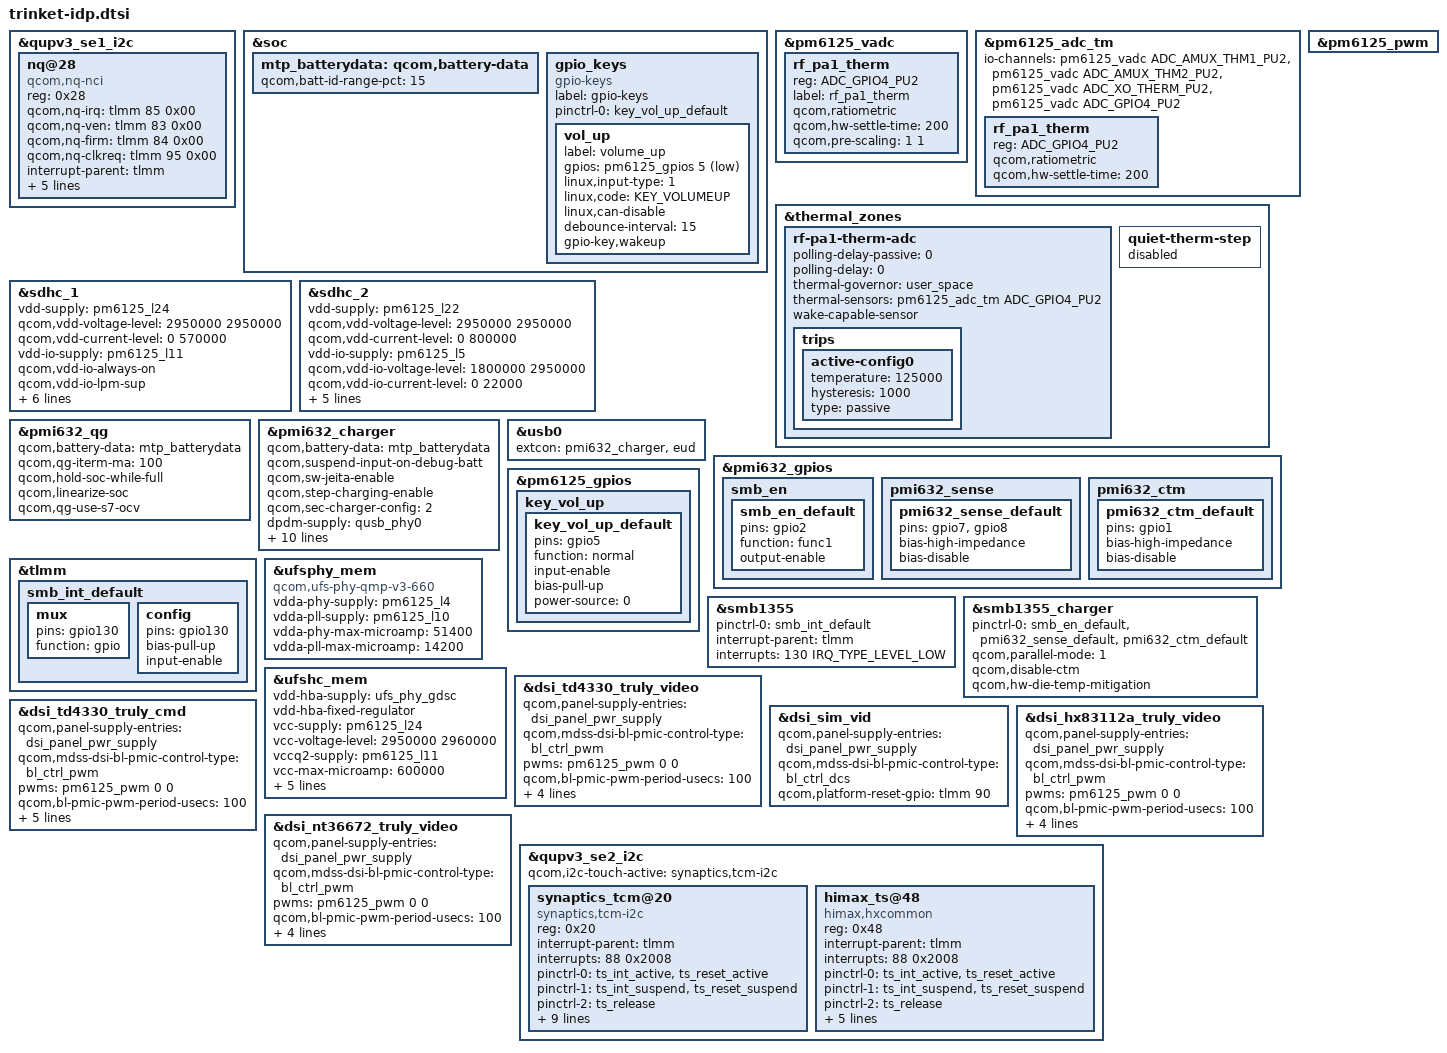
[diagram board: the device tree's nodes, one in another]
/*
 * Copyright (c) 2018-2019, The Linux Foundation. All rights reserved.
 *
 * This program is free software; you can redistribute it and/or modify
 * it under the terms of the GNU General Public License version 2 and
 * only version 2 as published by the Free Software Foundation.
 *
 * This program is distributed in the hope that it will be useful,
 * but WITHOUT ANY WARRANTY; without even the implied warranty of
 * MERCHANTABILITY or FITNESS FOR A PARTICULAR PURPOSE.  See the
 * GNU General Public License for more details.
 */
#include <dt-bindings/gpio/gpio.h>
#include <dt-bindings/input/input.h>
#include <dt-bindings/iio/qcom,spmi-vadc.h>
#include "trinket-thermal-overlay.dtsi"
#include "trinket-sde-display.dtsi"
#include <dt-bindings/clock/qcom,gcc-trinket.h>
#include "trinket-camera-sensor-idp.dtsi"

&qupv3_se1_i2c {
	status = "ok";
	#include "smb1355.dtsi"
};

&soc {
	mtp_batterydata: qcom,battery-data {
		qcom,batt-id-range-pct = <15>;
		#include "qg-batterydata-ascent-3450mah.dtsi"
		#include "qg-batterydata-mlp356477-2800mah.dtsi"
	};
};

&pm6125_vadc {
	rf_pa1_therm {
		reg = <ADC_GPIO4_PU2>;
		label = "rf_pa1_therm";
		qcom,ratiometric;
		qcom,hw-settle-time = <200>;
		qcom,pre-scaling = <1 1>;
	};
};

&pm6125_adc_tm {
	io-channels = <&pm6125_vadc ADC_AMUX_THM1_PU2>,
			<&pm6125_vadc ADC_AMUX_THM2_PU2>,
			<&pm6125_vadc ADC_XO_THERM_PU2>,
			<&pm6125_vadc ADC_GPIO4_PU2>;

	rf_pa1_therm {
		reg = <ADC_GPIO4_PU2>;
		qcom,ratiometric;
		qcom,hw-settle-time = <200>;
	};
};

&thermal_zones {
	rf-pa1-therm-adc {
		polling-delay-passive = <0>;
		polling-delay = <0>;
		thermal-governor = "user_space";
		thermal-sensors = <&pm6125_adc_tm ADC_GPIO4_PU2>;
		wake-capable-sensor;
		trips {
			active-config0 {
				temperature = <125000>;
				hysteresis = <1000>;
				type = "passive";
			};
		};
	};

	quiet-therm-step {
		status = "disabled";
	};
};

&qupv3_se1_i2c {
	status = "ok";
	nq@28 {
		compatible = "qcom,nq-nci";
		reg = <0x28>;
		qcom,nq-irq = <&tlmm 85 0x00>;
		qcom,nq-ven = <&tlmm 83 0x00>;
		qcom,nq-firm = <&tlmm 84 0x00>;
		qcom,nq-clkreq = <&tlmm 95 0x00>;
		interrupt-parent = <&tlmm>;
		interrupts = <85 0>;
		interrupt-names = "nfc_irq";
		pinctrl-names = "nfc_active", "nfc_suspend";
		pinctrl-0 = <&nfc_int_active &nfc_enable_active
				&nfc_clk_req_active>;
		pinctrl-1 = <&nfc_int_suspend &nfc_enable_suspend
				&nfc_clk_req_suspend>;
	};
};

&sdhc_1 {
	vdd-supply = <&pm6125_l24>;
	qcom,vdd-voltage-level = <2950000 2950000>;
	qcom,vdd-current-level = <0 570000>;

	vdd-io-supply = <&pm6125_l11>;
	qcom,vdd-io-always-on;
	qcom,vdd-io-lpm-sup;
	qcom,vdd-io-voltage-level = <1800000 1800000>;
	qcom,vdd-io-current-level = <0 325000>;

	pinctrl-names = "active", "sleep";
	pinctrl-0 = <&sdc1_clk_on &sdc1_cmd_on &sdc1_data_on
					&sdc1_rclk_on>;
	pinctrl-1 = <&sdc1_clk_off &sdc1_cmd_off &sdc1_data_off
					&sdc1_rclk_off>;

	status = "ok";
};

&sdhc_2 {
	vdd-supply = <&pm6125_l22>;
	qcom,vdd-voltage-level = <2950000 2950000>;
	qcom,vdd-current-level = <0 800000>;

	vdd-io-supply = <&pm6125_l5>;
	qcom,vdd-io-voltage-level = <1800000 2950000>;
	qcom,vdd-io-current-level = <0 22000>;

	pinctrl-names = "active", "sleep";
	pinctrl-0 = <&sdc2_clk_on  &sdc2_cmd_on &sdc2_data_on &sdc2_cd_on>;
	pinctrl-1 = <&sdc2_clk_off &sdc2_cmd_off &sdc2_data_off &sdc2_cd_off>;

	cd-gpios = <&tlmm 98 GPIO_ACTIVE_LOW>;

	status = "ok";
};

&pmi632_qg {
	qcom,battery-data = <&mtp_batterydata>;
	qcom,qg-iterm-ma = <100>;
	qcom,hold-soc-while-full;
	qcom,linearize-soc;
	qcom,qg-use-s7-ocv;
};

&pmi632_charger {
	qcom,battery-data = <&mtp_batterydata>;
	qcom,suspend-input-on-debug-batt;
	qcom,sw-jeita-enable;
	qcom,step-charging-enable;
	/* SMB1355 only */
	qcom,sec-charger-config = <2>;
	dpdm-supply = <&qusb_phy0>;
	qcom,charger-temp-max = <800>;
	qcom,smb-temp-max = <800>;
	qcom,auto-recharge-soc = <98>;
	qcom,flash-disable-soc = <10>;
	qcom,hw-die-temp-mitigation;
	qcom,hw-connector-mitigation;
	qcom,connector-internal-pull-kohm = <100>;
	qcom,float-option = <1>;
	qcom,thermal-mitigation = <3000000 2500000
			2000000 1500000 1000000 500000>;
};

&usb0 {
	extcon = <&pmi632_charger>, <&eud>;
};

&pmi632_gpios {
	smb_en {
		smb_en_default: smb_en_default {
			pins = "gpio2";
			function = "func1";
			output-enable;
		};
	};

	pmi632_sense {
		/* GPIO 7 and 8 are external-sense pins for PMI632 */
		pmi632_sense_default: pmi632_sense_default {
			pins = "gpio7", "gpio8";
			bias-high-impedance;	/* disable the GPIO */
			bias-disable;		/* no-pull */
		};
	};

	pmi632_ctm {
		/* Disable GPIO1 for h/w base mitigation */
		pmi632_ctm_default: pmi632_ctm_default {
			pins = "gpio1";
			bias-high-impedance;	/* disable the GPIO */
			bias-disable;		/* no-pull */
		};
	};
};

&pm6125_gpios {
	key_vol_up {
		key_vol_up_default: key_vol_up_default {
			pins = "gpio5";
			function = "normal";
			input-enable;
			bias-pull-up;
			power-source = <0>;
		};
	};
};

&soc {
	gpio_keys {
		compatible = "gpio-keys";
		label = "gpio-keys";

		pinctrl-names = "default";
		pinctrl-0 = <&key_vol_up_default>;

		vol_up {
			label = "volume_up";
			gpios = <&pm6125_gpios 5 GPIO_ACTIVE_LOW>;
			linux,input-type = <1>;
			linux,code = <KEY_VOLUMEUP>;
			linux,can-disable;
			debounce-interval = <15>;
			gpio-key,wakeup;
		};
	};
};

&tlmm {
	smb_int_default: smb_int_default {
		mux {
			pins = "gpio130";
			function = "gpio";
		};
		config {
			pins = "gpio130";
			bias-pull-up;
			input-enable;
		};
	};
};

&smb1355 {
	pinctrl-names = "default";
	pinctrl-0 = <&smb_int_default>;
	interrupt-parent = <&tlmm>;
	interrupts = <130 IRQ_TYPE_LEVEL_LOW>;
	status = "ok";
};

&smb1355_charger {
	pinctrl-names = "default";
	pinctrl-0 = <&smb_en_default &pmi632_sense_default &pmi632_ctm_default>;
	qcom,parallel-mode = <1>;
	qcom,disable-ctm;
	qcom,hw-die-temp-mitigation;
	status = "ok";
};

&ufsphy_mem {
	compatible = "qcom,ufs-phy-qmp-v3-660";

	vdda-phy-supply = <&pm6125_l4>; /* 0.9v */
	vdda-pll-supply = <&pm6125_l10>; /* 1.8v */
	vdda-phy-max-microamp = <51400>;
	vdda-pll-max-microamp = <14200>;

	status = "ok";
};

&ufshc_mem {
	vdd-hba-supply = <&ufs_phy_gdsc>;
	vdd-hba-fixed-regulator;
	vcc-supply = <&pm6125_l24>;
	vcc-voltage-level = <2950000 2960000>;
	vccq2-supply = <&pm6125_l11>;
	vcc-max-microamp = <600000>;
	vccq2-max-microamp = <600000>;

	qcom,vddp-ref-clk-supply = <&pm6125_l18>;
	qcom,vddp-ref-clk-max-microamp = <100>;
	qcom,vddp-ref-clk-min-uV = <1200000>;
	qcom,vddp-ref-clk-max-uV = <1232000>;

	status = "ok";
};

&pm6125_pwm {
	status = "ok";
};

&dsi_td4330_truly_video {
	qcom,panel-supply-entries = <&dsi_panel_pwr_supply>;
	qcom,mdss-dsi-bl-pmic-control-type = "bl_ctrl_pwm";
	pwms = <&pm6125_pwm 0 0>;
	qcom,bl-pmic-pwm-period-usecs = <100>;
	qcom,mdss-dsi-bl-min-level = <1>;
	qcom,mdss-dsi-bl-max-level = <4095>;
	qcom,platform-reset-gpio = <&tlmm 90 0>;
	qcom,platform-bklight-en-gpio = <&pmi632_gpios 6 0>;
};

&dsi_td4330_truly_cmd {
	qcom,panel-supply-entries = <&dsi_panel_pwr_supply>;
	qcom,mdss-dsi-bl-pmic-control-type = "bl_ctrl_pwm";
	pwms = <&pm6125_pwm 0 0>;
	qcom,bl-pmic-pwm-period-usecs = <100>;
	qcom,mdss-dsi-bl-min-level = <1>;
	qcom,mdss-dsi-bl-max-level = <4095>;
	qcom,platform-te-gpio = <&tlmm 89 0>;
	qcom,platform-reset-gpio = <&tlmm 90 0>;
	qcom,platform-bklight-en-gpio = <&pmi632_gpios 6 0>;
};

&dsi_sim_vid {
	qcom,panel-supply-entries = <&dsi_panel_pwr_supply>;
	qcom,mdss-dsi-bl-pmic-control-type = "bl_ctrl_dcs";
	qcom,platform-reset-gpio = <&tlmm 90 0>;
};

&dsi_hx83112a_truly_video {
	qcom,panel-supply-entries = <&dsi_panel_pwr_supply>;
	qcom,mdss-dsi-bl-pmic-control-type = "bl_ctrl_pwm";
	pwms = <&pm6125_pwm 0 0>;
	qcom,bl-pmic-pwm-period-usecs = <100>;
	qcom,mdss-dsi-bl-min-level = <1>;
	qcom,mdss-dsi-bl-max-level = <4095>;
	qcom,platform-reset-gpio = <&tlmm 90 0>;
	qcom,platform-bklight-en-gpio = <&pmi632_gpios 6 0>;
};

&dsi_nt36672_truly_video {
	qcom,panel-supply-entries = <&dsi_panel_pwr_supply>;
	qcom,mdss-dsi-bl-pmic-control-type = "bl_ctrl_pwm";
	pwms = <&pm6125_pwm 0 0>;
	qcom,bl-pmic-pwm-period-usecs = <100>;
	qcom,mdss-dsi-bl-min-level = <1>;
	qcom,mdss-dsi-bl-max-level = <4095>;
	qcom,platform-reset-gpio = <&tlmm 90 0>;
	qcom,platform-bklight-en-gpio = <&pmi632_gpios 6 0>;
};

&qupv3_se2_i2c {
	status = "okay";
	qcom,i2c-touch-active="synaptics,tcm-i2c";

	synaptics_tcm@20 {
		compatible = "synaptics,tcm-i2c";
		reg = <0x20>;
		interrupt-parent = <&tlmm>;
		interrupts = <88 0x2008>;
		pinctrl-names = "pmx_ts_active","pmx_ts_suspend",
					"pmx_ts_release";
		pinctrl-0 = <&ts_int_active &ts_reset_active>;
		pinctrl-1 = <&ts_int_suspend &ts_reset_suspend>;
		pinctrl-2 = <&ts_release>;
		synaptics,irq-gpio = <&tlmm 88 0x2008>;
		synaptics,irq-on-state = <0>;
		synaptics,reset-gpio = <&tlmm 87 0x00>;
		synaptics,reset-on-state = <0>;
		synaptics,reset-active-ms = <20>;
		synaptics,reset-delay-ms = <200>;
		synaptics,power-delay-ms = <200>;
		synaptics,ubl-i2c-addr = <0x20>;
		synaptics,y-flip;
	};

	himax_ts@48 {
		compatible = "himax,hxcommon";
		reg = <0x48>;
		interrupt-parent = <&tlmm>;
		interrupts = <88 0x2008>;
		pinctrl-names = "pmx_ts_active","pmx_ts_suspend",
			"pmx_ts_release";
		pinctrl-0 = <&ts_int_active &ts_reset_active>;
		pinctrl-1 = <&ts_int_suspend &ts_reset_suspend>;
		pinctrl-2 = <&ts_release>;
		himax,panel-coords = <0 1080 0 2160>;
		himax,display-coords = <0 1080 0 2160>;
		himax,irq-gpio = <&tlmm 88 0x00>;
		himax,rst-gpio = <&tlmm 87 0x00>;
		report_type = <1>;
	};
};
